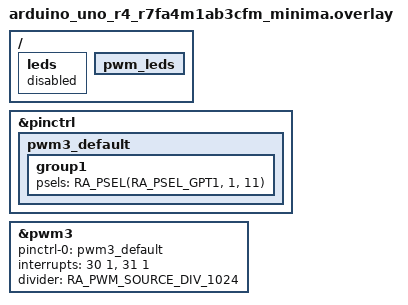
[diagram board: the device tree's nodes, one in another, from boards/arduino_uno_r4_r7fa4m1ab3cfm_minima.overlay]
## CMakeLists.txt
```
# SPDX-License-Identifier: Apache-2.0

cmake_minimum_required(VERSION 3.28.0)
find_package(Zephyr REQUIRED HINTS $ENV{ZEPHYR_BASE})
project(fade_led)

target_sources(app PRIVATE src/main.c)
```

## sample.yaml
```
sample:
  name: Fade LED
tests:
  sample.basic.fade_led:
    tags:
      - drivers
      - pwm
    depends_on: pwm
    harness: led
    filter: dt_alias_exists("pwm-led0") and dt_compat_enabled("pwm-leds")
    integration_platforms:
      - nrf51dk_nrf51422
```

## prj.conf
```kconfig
CONFIG_PRINTK=y
CONFIG_PWM=y
CONFIG_LOG=y
CONFIG_PWM_LOG_LEVEL_DBG=y
```

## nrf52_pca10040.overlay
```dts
&pwm0 {
	status = "ok";
	ch0-pin = <17>;
	ch0-inverted;
	ch1-pin = <18>;
};
```

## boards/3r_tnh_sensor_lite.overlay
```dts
/*
 * Copyright (c) 2026 MASSDRIVER EI (massdriver.space)
 *
 * SPDX-License-Identifier: Apache-2.0
 */

/ {
	leds {
		status = "disabled";
	};
};

&pwmleds {
	status = "okay";
};

&pwm1 {
	pinctrl-0 = <&pwm1_default>;
	pinctrl-names = "default";
	status = "okay";
};
```

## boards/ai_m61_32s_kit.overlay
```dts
/*
 * Copyright (c) 2026 MASSDRIVER EI (massdriver.space)
 *
 * SPDX-License-Identifier: Apache-2.0
 */

/ {
	leds {
		status = "disabled";
	};
};

&pwmleds {
	status = "okay";
};

&pwm0 {
	pinctrl-0 = <&blue_pwm_pinctrl>;
	pinctrl-names = "default";
	status = "okay";
};
```

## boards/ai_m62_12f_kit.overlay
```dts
/*
 * Copyright (c) 2025 MASSDRIVER EI (massdriver.space)
 *
 * SPDX-License-Identifier: Apache-2.0
 */

/ {
	leds {
		status = "disabled";
	};
};

&pwmleds {
	status = "okay";
};

&pwm0 {
	status = "okay";
	pinctrl-0 = <&white_pwm_pinctrl>;
	pinctrl-names = "default";
};
```

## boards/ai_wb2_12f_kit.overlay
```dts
/*
 * Copyright (c) 2025 MASSDRIVER EI (massdriver.space)
 *
 * SPDX-License-Identifier: Apache-2.0
 */

/ {
	leds {
		status = "disabled";
	};
};

&pwmleds {
	status = "okay";
};

&pwm0 {
	pinctrl-0 = <&blue_pwm_pinctrl>;
	pinctrl-names = "default";
	status = "okay";
};
```

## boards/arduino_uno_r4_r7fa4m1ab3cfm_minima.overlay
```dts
/*
 * Copyright (c) 2025 TOKITA Hiroshi
 *
 * SPDX-License-Identifier: Apache-2.0
 */

#include <zephyr/dt-bindings/pwm/pwm.h>
#include <zephyr/dt-bindings/pwm/ra_pwm.h>

/ {
	leds {
		status = "disabled";
	};

	pwm_leds {
		status = "okay";
	};
};

&pinctrl {
	pwm3_default: pwm3_default {
		group1 {
			/* GTIOC3A */
			psels = <RA_PSEL(RA_PSEL_GPT1, 1, 11)>;
		};
	};
};

&pwm3 {
	pinctrl-0 = <&pwm3_default>;
	pinctrl-names = "default";
	interrupts = <30 1>, <31 1>;
	interrupt-names = "gtioca", "overflow";
	divider = <RA_PWM_SOURCE_DIV_1024>;
	status = "okay";
};
```

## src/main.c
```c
/*
 * Copyright (c) 2016 Intel Corporation
 * Copyright (c) 2020 Nordic Semiconductor ASA
 *
 * SPDX-License-Identifier: Apache-2.0
 */

/**
 * @file Sample app to demonstrate PWM-based LED fade
 */

#include <zephyr/kernel.h>
#include <zephyr/sys/printk.h>
#include <zephyr/device.h>
#include <zephyr/drivers/pwm.h>

#define PWM_LED_ALIAS(i) DT_ALIAS(_CONCAT(pwm_led, i))
#define PWM_LED_IS_OKAY(i) DT_NODE_HAS_STATUS_OKAY(DT_PARENT(PWM_LED_ALIAS(i)))
#define PWM_LED(i, _) IF_ENABLED(PWM_LED_IS_OKAY(i), (PWM_DT_SPEC_GET(PWM_LED_ALIAS(i)),))

#define MAX_LEDS 10
static const struct pwm_dt_spec pwm_leds[] = {LISTIFY(MAX_LEDS, PWM_LED, ())};

#define NUM_STEPS	50U
#define SLEEP_MSEC	25U

static void update_fade_state(size_t i, uint32_t *pulse_widths, uint32_t *steps, uint8_t *dirs)
{
	if (dirs[i] == 1) {
		if (pulse_widths[i] + steps[i] >= pwm_leds[i].period) {
			pulse_widths[i] = pwm_leds[i].period;
			dirs[i] = 0U;
		} else {
			pulse_widths[i] += steps[i];
		}
	} else {
		if (pulse_widths[i] <= steps[i]) {
			pulse_widths[i] = 0;
			dirs[i] = 1U;
		} else {
			pulse_widths[i] -= steps[i];
		}
	}
}

int main(void)
{
	uint32_t pulse_widths[ARRAY_SIZE(pwm_leds)];
	uint32_t steps[ARRAY_SIZE(pwm_leds)];
	uint8_t dirs[ARRAY_SIZE(pwm_leds)];
	int ret;

	printk("PWM-based LED fade. Found %d LEDs\n", ARRAY_SIZE(pwm_leds));

	for (size_t i = 0; i < ARRAY_SIZE(pwm_leds); i++) {
		pulse_widths[i] = 0;
		steps[i] = pwm_leds[i].period / NUM_STEPS;
		dirs[i] = 1U;
		if (!pwm_is_ready_dt(&pwm_leds[i])) {
			printk("Error: PWM device %s is not ready\n", pwm_leds[i].dev->name);
			return 0;
		}
	}

	while (1) {
		for (size_t i = 0; i < ARRAY_SIZE(pwm_leds); i++) {
			ret = pwm_set_pulse_dt(&pwm_leds[i], pulse_widths[i]);
			if (ret) {
				printk("Error %d: failed to set pulse width for LED %d\n", ret, i);
			}
			printk("LED %d: Using pulse width %d%%\n", i,
			       100 * pulse_widths[i] / pwm_leds[i].period);

			update_fade_state(i, pulse_widths, steps, dirs);
		}

		k_sleep(K_MSEC(SLEEP_MSEC));
	}
	return 0;
}
```
